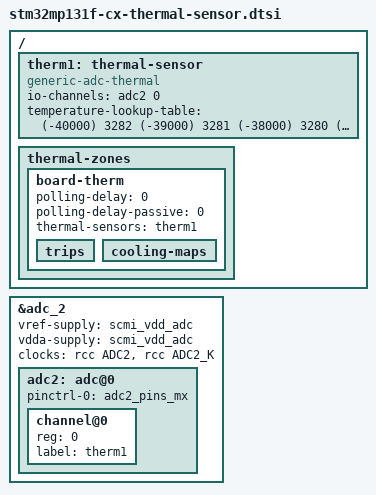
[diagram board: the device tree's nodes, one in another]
&adc_2 {
    vref-supply = <&scmi_vdd_adc>;
    vdda-supply = <&scmi_vdd_adc>;
    clocks = <&rcc ADC2>, <&rcc ADC2_K>;
    clock-names = "bus", "adc";
    status = "okay";

    adc2: adc@0 {
        pinctrl-names = "default";
        pinctrl-0 = <&adc2_pins_mx>;
        #io-channel-cells = <1>;
        status = "okay";

        channel@0 {
            reg = <0>;
            label = "therm1";
        };
    };
};

/ {
    therm1: thermal-sensor {
        compatible = "generic-adc-thermal";
        #thermal-sensor-cells = <0>;
        io-channels = <&adc2 0>;
        io-channel-names = "sensor-channel";
        temperature-lookup-table = <
            // Milli-Celsius to ADC Milli-Voltage
            (-40000) 3282
            (-39000) 3281
            (-38000) 3280
            (-37000) 3279
            (-36000) 3278
            (-35000) 3277
            (-34000) 3276
            (-33000) 3274
            (-32000) 3273
            (-31000) 3272
            (-30000) 3270
            (-29000) 3269
            (-28000) 3267
            (-27000) 3265
            (-26000) 3264
            (-25000) 3262
            (-24000) 3260
            (-23000) 3258
            (-22000) 3256
            (-21000) 3254
            (-20000) 3252
            (-19000) 3249
            (-18000) 3247
            (-17000) 3244
            (-16000) 3242
            (-15000) 3239
            (-14000) 3236
            (-13000) 3233
            (-12000) 3230
            (-11000) 3227
            (-10000) 3224
            (-9000)  3220
            (-8000)  3217
            (-7000)  3213
            (-6000)  3209
            (-5000)  3205
            (-4000)  3201
            (-3000)  3197
            (-2000)  3192
            (-1000)  3188
            0        3183
            500      3180
            1000     3178
            1500     3175
            2000     3173
            2500     3170
            3000     3168
            3500     3165
            4000     3162
            4500     3159
            5000     3156
            5500     3154
            6000     3151
            6500     3148
            7000     3145
            7500     3142
            8000     3138
            8500     3135
            9000     3132
            9500     3129
            10000    3125
            10500    3122
            11000    3119
            11500    3115
            12000    3112
            12500    3108
            13000    3104
            13500    3101
            14000    3097
            14500    3093
            15000    3089
            15500    3085
            16000    3081
            16500    3077
            17000    3073
            17500    3069
            18000    3065
            18500    3061
            19000    3056
            19500    3052
            20000    3047
            20500    3043
            21000    3038
            21500    3034
            22000    3029
            22500    3024
            23000    3019
            23500    3015
            24000    3010
            24500    3005
            25000    2999
            25500    2994
            26000    2989
            26500    2984
            27000    2979
            27500    2973
            28000    2968
            28500    2962
            29000    2957
            29500    2951
            30000    2945
            30500    2939
            31000    2933
            31500    2928
            32000    2921
            32500    2915
            33000    2909
            33500    2903
            34000    2897
            34500    2890
            35000    2884
            35500    2878
            36000    2871
            36500    2864
            37000    2858
            37500    2851
            38000    2844
            38500    2837
            39000    2830
            39500    2823
            40000    2816
            40500    2809
            41000    2802
            41500    2794
            42000    2787
            42500    2780
            43000    2772
            43500    2764
            44000    2757
            44500    2749
            45000    2741
            45500    2733
            46000    2725
            46500    2718
            47000    2709
            47500    2701
            48000    2693
            48500    2685
            49000    2677
            49500    2668
            50000    2660
            50500    2651
            51000    2643
            51500    2634
            52000    2625
            52500    2617
            53000    2608
            53500    2599
            54000    2590
            54500    2581
            55000    2572
            55500    2563
            56000    2554
            56500    2545
            57000    2535
            57500    2526
            58000    2517
            58500    2507
            59000    2498
            59500    2488
            60000    2478
            60500    2469
            61000    2459
            61500    2449
            62000    2439
            62500    2430
            63000    2420
            63500    2410
            64000    2400
            64500    2390
            65000    2380
            65500    2370
            66000    2360
            66500    2349
            67000    2339
            67500    2329
            68000    2319
            68500    2308
            69000    2298
            69500    2288
            70000    2277
            70500    2267
            71000    2256
            71500    2246
            72000    2235
            72500    2224
            73000    2214
            73500    2203
            74000    2192
            74500    2182
            75000    2171
            75500    2160
            76000    2149
            76500    2139
            77000    2128
            77500    2117
            78000    2106
            78500    2095
            79000    2084
            79500    2074
            80000    2063
            80500    2052
            81000    2041
            81500    2030
            82000    2019
            82500    2008
            83000    1997
            83500    1986
            84000    1975
            84500    1964
            85000    1953
            85500    1942
            86000    1931
            86500    1920
            87000    1909
            87500    1899
            88000    1887
            88500    1877
            89000    1866
            89500    1855
            90000    1844
            90500    1833
            91000    1822
            91500    1811
            92000    1800
            92500    1790
            93000    1779
            93500    1768
            94000    1757
            94500    1746
            95000    1736
            95500    1725
            96000    1714
            96500    1703
            97000    1693
            97500    1682
            98000    1671
            98500    1661
            99000    1650
            99500    1640
            100000   1629
            100500   1618
            101000   1608
            101500   1598
            102000   1587
            102500   1577
            103000   1566
            103500   1556
            104000   1545
            104500   1535
            105000   1525
            105500   1515
            106000   1504
            106500   1494
            107000   1484
            107500   1474
            108000   1464
            108500   1454
            109000   1445
            109500   1435
            110000   1425
            110500   1415
            111000   1405
            111500   1395
            112000   1385
            112500   1376
            113000   1366
            113500   1357
            114000   1347
            114500   1338
            115000   1328
            115500   1319
            116000   1309
            116500   1300
            117000   1291
            117500   1282
            118000   1272
            118500   1263
            119000   1254
            119500   1245
            120000   1236
            120500   1227
            121000   1217
            121500   1209
            122000   1200
            122500   1192
            123000   1183
            123500   1174
            124000   1165
            124500   1157
            125000   1148
        >;
        status = "okay";
    };


    thermal-zones {
        board-therm {
            polling-delay = <0>; /* milliseconds */
            polling-delay-passive = <0>; /* milliseconds */
            thermal-sensors = <&therm1>;

            trips {
            };

            cooling-maps {
            };
        };
    };
};
